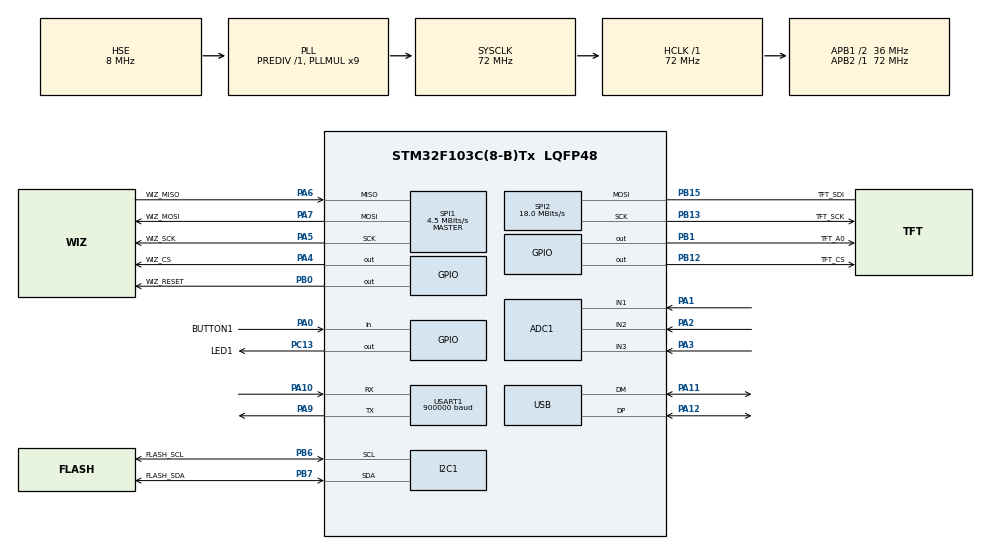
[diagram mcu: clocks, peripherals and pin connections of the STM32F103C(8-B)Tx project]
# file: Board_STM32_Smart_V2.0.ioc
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ADC1.Channel-0\#ChannelRegularConversion=ADC_CHANNEL_1
ADC1.Channel-1\#ChannelRegularConversion=ADC_CHANNEL_2
ADC1.Channel-2\#ChannelRegularConversion=ADC_CHANNEL_3
ADC1.ContinuousConvMode=DISABLE
ADC1.ExternalTrigConv=ADC_EXTERNALTRIGCONV_T3_TRGO
ADC1.NbrOfConversion=3
ADC1.NbrOfConversionFlag=1
ADC1.Rank-0\#ChannelRegularConversion=1
ADC1.Rank-1\#ChannelRegularConversion=2
ADC1.Rank-2\#ChannelRegularConversion=3
ADC1.SamplingTime-0\#ChannelRegularConversion=ADC_SAMPLETIME_28CYCLES_5
ADC1.SamplingTime-1\#ChannelRegularConversion=ADC_SAMPLETIME_28CYCLES_5
ADC1.SamplingTime-2\#ChannelRegularConversion=ADC_SAMPLETIME_28CYCLES_5
ADC1.master=1
Dma.ADC1.2.Direction=DMA_PERIPH_TO_MEMORY
Dma.ADC1.2.Instance=DMA1_Channel1
Dma.ADC1.2.MemDataAlignment=DMA_MDATAALIGN_HALFWORD
Dma.ADC1.2.MemInc=DMA_MINC_ENABLE
Dma.ADC1.2.Mode=DMA_CIRCULAR
Dma.ADC1.2.PeriphDataAlignment=DMA_PDATAALIGN_WORD
Dma.ADC1.2.PeriphInc=DMA_PINC_DISABLE
Dma.ADC1.2.Priority=DMA_PRIORITY_LOW
Dma.Request0=USART1_RX
Dma.Request1=TIM2_UP
Dma.Request2=ADC1
Dma.TIM2_UP.1.Direction=DMA_MEMORY_TO_PERIPH
Dma.TIM2_UP.1.Instance=DMA1_Channel2
Dma.TIM2_UP.1.MemDataAlignment=DMA_MDATAALIGN_BYTE
Dma.TIM2_UP.1.MemInc=DMA_MINC_ENABLE
Dma.TIM2_UP.1.Mode=DMA_CIRCULAR
Dma.TIM2_UP.1.PeriphDataAlignment=DMA_PDATAALIGN_WORD
Dma.TIM2_UP.1.PeriphInc=DMA_PINC_DISABLE
Dma.TIM2_UP.1.Priority=DMA_PRIORITY_LOW
Dma.USART1_RX.0.Direction=DMA_PERIPH_TO_MEMORY
Dma.USART1_RX.0.Instance=DMA1_Channel5
Dma.USART1_RX.0.MemDataAlignment=DMA_MDATAALIGN_BYTE
Dma.USART1_RX.0.MemInc=DMA_MINC_ENABLE
Dma.USART1_RX.0.Mode=DMA_CIRCULAR
Dma.USART1_RX.0.PeriphDataAlignment=DMA_PDATAALIGN_BYTE
Dma.USART1_RX.0.PeriphInc=DMA_PINC_DISABLE
Dma.USART1_RX.0.Priority=DMA_PRIORITY_MEDIUM
Mcu.Family=STM32F1
Mcu.Name=STM32F103C(8-B)Tx
Mcu.Package=LQFP48
NVIC.DMA1_Channel1_IRQn=true\:0\:0\:false\:false\:true\:false\:true\:true
NVIC.DMA1_Channel2_IRQn=true\:0\:0\:false\:false\:true\:false\:true\:true
NVIC.DMA1_Channel5_IRQn=true\:1\:0\:true\:false\:true\:false\:true\:true
NVIC.PriorityGroup=NVIC_PRIORITYGROUP_4
NVIC.TIM2_IRQn=true\:4\:0\:true\:false\:true\:true\:false\:true
NVIC.TIM4_IRQn=true\:7\:0\:true\:false\:true\:true\:false\:true
NVIC.USART1_IRQn=true\:2\:0\:true\:false\:true\:true\:false\:true
NVIC.USB_LP_CAN1_RX0_IRQn=true\:3\:0\:true\:false\:true\:false\:true\:true
PA0-WKUP.GPIO_Label=BUTTON1
PA0-WKUP.Signal=GPIO_Input
PA1.Signal=ADCx_IN1
PA10.Mode=Asynchronous
PA10.Signal=USART1_RX
PA11.Mode=Device
PA11.Signal=USB_DM
PA12.Mode=Device
PA12.Signal=USB_DP
PA13.Mode=Serial_Wire
PA13.Signal=SYS_JTMS-SWDIO
PA14.Mode=Serial_Wire
PA14.Signal=SYS_JTCK-SWCLK
PA2.Signal=ADCx_IN2
PA3.Signal=ADCx_IN3
PA4.GPIO_Label=WIZ_CS
PA4.Signal=GPIO_Output
PA5.GPIO_Label=WIZ_SCK
PA5.Mode=Full_Duplex_Master
PA5.Signal=SPI1_SCK
PA6.GPIO_Label=WIZ_MISO
PA6.Mode=Full_Duplex_Master
PA6.Signal=SPI1_MISO
PA7.GPIO_Label=WIZ_MOSI
PA7.Mode=Full_Duplex_Master
PA7.Signal=SPI1_MOSI
PA9.Mode=Asynchronous
PA9.Signal=USART1_TX
PB0.GPIO_Label=WIZ_RESET
PB0.Signal=GPIO_Output
PB1.GPIO_Label=TFT_A0
PB1.Signal=GPIO_Output
PB12.GPIO_Label=TFT_CS
PB12.Signal=GPIO_Output
PB13.GPIO_Label=TFT_SCK
PB13.Mode=Simplex_Bidirectional_Master
PB13.Signal=SPI2_SCK
PB15.GPIO_Label=TFT_SDI
PB15.Mode=Simplex_Bidirectional_Master
PB15.Signal=SPI2_MOSI
PB6.GPIO_Label=FLASH_SCL
PB6.Mode=I2C
PB6.Signal=I2C1_SCL
PB7.GPIO_Label=FLASH_SDA
PB7.Mode=I2C
PB7.Signal=I2C1_SDA
PC13-TAMPER-RTC.GPIO_Label=LED1
PC13-TAMPER-RTC.Signal=GPIO_Output
PC14-OSC32_IN.Mode=LSE-External-Oscillator
PC14-OSC32_IN.Signal=RCC_OSC32_IN
PC15-OSC32_OUT.Mode=LSE-External-Oscillator
PC15-OSC32_OUT.Signal=RCC_OSC32_OUT
PD0-OSC_IN.Mode=HSE-External-Oscillator
PD0-OSC_IN.Signal=RCC_OSC_IN
PD1-OSC_OUT.Mode=HSE-External-Oscillator
PD1-OSC_OUT.Signal=RCC_OSC_OUT
ProjectManager.HeapSize=0x100
ProjectManager.StackSize=0x600
ProjectManager.TargetToolchain=STM32CubeIDE
RCC.ADCPresc=RCC_ADCPCLK2_DIV6
RCC.AHBFreq_Value=72000000
RCC.APB1CLKDivider=RCC_HCLK_DIV2
RCC.APB1Freq_Value=36000000
RCC.APB1TimFreq_Value=72000000
RCC.APB2Freq_Value=72000000
RCC.APB2TimFreq_Value=72000000
RCC.HCLKFreq_Value=72000000
RCC.PLLMUL=RCC_PLL_MUL9
RCC.SYSCLKFreq_VALUE=72000000
RCC.SYSCLKSource=RCC_SYSCLKSOURCE_PLLCLK
RCC.USBFreq_Value=48000000
RCC.USBPrescaler=RCC_USBCLKSOURCE_PLL_DIV1_5
SH.ADCx_IN1.0=ADC1_IN1,IN1
SH.ADCx_IN2.0=ADC1_IN2,IN2
SH.ADCx_IN3.0=ADC1_IN3,IN3
SPI1.BaudRatePrescaler=SPI_BAUDRATEPRESCALER_16
SPI1.CalculateBaudRate=4.5 MBits/s
SPI1.Direction=SPI_DIRECTION_2LINES
SPI1.Mode=SPI_MODE_MASTER
SPI1.VirtualType=VM_MASTER
SPI2.CalculateBaudRate=18.0 MBits/s
SPI2.Direction=SPI_DIRECTION_1LINE
SPI2.Mode=SPI_MODE_MASTER
SPI2.VirtualType=VM_MASTER
TIM2.AutoReloadPreload=TIM_AUTORELOAD_PRELOAD_DISABLE
TIM2.Period=89
TIM2.TIM_MasterOutputTrigger=TIM_TRGO_UPDATE
TIM3.Period=999
TIM3.Prescaler=71
TIM3.TIM_MasterOutputTrigger=TIM_TRGO_UPDATE
TIM4.Period=9999
TIM4.Prescaler=7199
TIM4.TIM_MasterOutputTrigger=TIM_TRGO_UPDATE
USART1.BaudRate=900000
USART1.VirtualMode=VM_ASYNC
USB_DEVICE.APP_RX_DATA_SIZE=64
USB_DEVICE.APP_TX_DATA_SIZE=64
USB_DEVICE.CLASS_NAME_FS=CDC
USB_DEVICE.VirtualMode=Cdc
USB_DEVICE.VirtualModeFS=Cdc_FS
VP_TIM2_VS_ClockSourceINT.Mode=Internal
VP_TIM3_VS_ClockSourceINT.Mode=Internal
VP_TIM4_VS_ClockSourceINT.Mode=Internal
VP_USB_DEVICE_VS_USB_DEVICE_CDC_FS.Mode=CDC_FS
board=custom

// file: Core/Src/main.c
/* USER CODE BEGIN Header */
/**
  ******************************************************************************
  * @file           : main.c
  * @brief          : Main program body
  ******************************************************************************
  * @attention
  *
  * Copyright (c) 2022 STMicroelectronics.
  * All rights reserved.
  *
  * This software is licensed under terms that can be found in the LICENSE file
  * in the root directory of this software component.
  * If no LICENSE file comes with this software, it is provided AS-IS.
  *
  ******************************************************************************
  */
/* USER CODE END Header */
#include "main.h"
#include "adc.h"
#include "dma.h"
#include "i2c.h"
#include "spi.h"
#include "tim.h"
#include "usart.h"
#include "gpio.h"

/* USER CODE BEGIN Includes */
#include "Components.h"
/* USER CODE END Includes */

/* USER CODE BEGIN PV */
//==============================================================================

//==============================================================================
/* USER CODE END PV */

void SystemClock_Config(void);
/* USER CODE BEGIN PFP */
//==============================================================================

//==============================================================================
/* USER CODE END PFP */

/* USER CODE BEGIN 0 */
//==============================================================================

//==============================================================================
/* USER CODE END 0 */

int main(void)
{

  /* MCU Configuration--------------------------------------------------------*/

  /* Reset of all peripherals, Initializes the Flash interface and the Systick. */
  HAL_Init();

  /* Configure the system clock */
  SystemClock_Config();

  /* Initialize all configured peripherals */
  MX_GPIO_Init();
  MX_DMA_Init();
  MX_TIM2_Init();
  MX_TIM3_Init();
  MX_TIM4_Init();
  MX_I2C1_Init();
  MX_SPI1_Init();
  MX_SPI2_Init();
  MX_ADC1_Init();
  MX_USART1_UART_Init();
  /* USER CODE BEGIN 2 */
  ComponentsInit(main);
  /* USER CODE END 2 */

  /* Infinite loop */
  /* USER CODE BEGIN WHILE */
  while (1)
  {
	ComponentsHandler();
    /* USER CODE END WHILE */

  }
}

void SystemClock_Config(void)
{
  RCC_OscInitTypeDef RCC_OscInitStruct = {0};
  RCC_ClkInitTypeDef RCC_ClkInitStruct = {0};
  RCC_PeriphCLKInitTypeDef PeriphClkInit = {0};

  /** Initializes the RCC Oscillators according to the specified parameters
  * in the RCC_OscInitTypeDef structure.
  */
  RCC_OscInitStruct.OscillatorType = RCC_OSCILLATORTYPE_HSE;
  RCC_OscInitStruct.HSEState = RCC_HSE_ON;
  RCC_OscInitStruct.HSEPredivValue = RCC_HSE_PREDIV_DIV1;
  RCC_OscInitStruct.HSIState = RCC_HSI_ON;
  RCC_OscInitStruct.PLL.PLLState = RCC_PLL_ON;
  RCC_OscInitStruct.PLL.PLLSource = RCC_PLLSOURCE_HSE;
  RCC_OscInitStruct.PLL.PLLMUL = RCC_PLL_MUL9;
  if (HAL_RCC_OscConfig(&RCC_OscInitStruct) != HAL_OK)
  {
    Error_Handler();
  }

  /** Initializes the CPU, AHB and APB buses clocks
  */
  RCC_ClkInitStruct.ClockType = RCC_CLOCKTYPE_HCLK|RCC_CLOCKTYPE_SYSCLK
                              |RCC_CLOCKTYPE_PCLK1|RCC_CLOCKTYPE_PCLK2;
  RCC_ClkInitStruct.SYSCLKSource = RCC_SYSCLKSOURCE_PLLCLK;
  RCC_ClkInitStruct.AHBCLKDivider = RCC_SYSCLK_DIV1;
  RCC_ClkInitStruct.APB1CLKDivider = RCC_HCLK_DIV2;
  RCC_ClkInitStruct.APB2CLKDivider = RCC_HCLK_DIV1;

  if (HAL_RCC_ClockConfig(&RCC_ClkInitStruct, FLASH_LATENCY_2) != HAL_OK)
  {
    Error_Handler();
  }
  PeriphClkInit.PeriphClockSelection = RCC_PERIPHCLK_ADC|RCC_PERIPHCLK_USB;
  PeriphClkInit.AdcClockSelection = RCC_ADCPCLK2_DIV6;
  PeriphClkInit.UsbClockSelection = RCC_USBCLKSOURCE_PLL_DIV1_5;
  if (HAL_RCCEx_PeriphCLKConfig(&PeriphClkInit) != HAL_OK)
  {
    Error_Handler();
  }
}

void Error_Handler(void)
{
  __disable_irq();
  while (1)
  {
  }
}
